# nrf9230_enga_celldsp register map
Vendor: Nordic Semiconductor; Series: nRF92; File version: 1
Registers are 32-bit, read-write, reset 0x0 unless marked. A register's access mark holds for its fields unless they carry their own. Offsets are from the block's base; [hi:lo] are bit positions; {n}, {i} and the like mark numbered series; 'fields as' and 'values as' point back to an identical list.

## HARQ — LTE HARQ
Base 0x4500C000
0x00 TASKS_STARTHARQCOMB wo — Start HARQ combining
  [0] TASKS_STARTHARQCOMB
    1=Trigger task
0x04 TASKS_STARTRM wo — Start rate de-mathcing and de-interleaving
  [0] TASKS_STARTRM
    1=Trigger task
0x08 TASKS_STARTUNPACK wo — Star HARQ process data unpacking operation
  [0] TASKS_STARTUNPACK
    1=Trigger task
0x0C TASKS_STARTPACK wo — Start HARQ process data packing operation
  [0] TASKS_STARTPACK
    1=Trigger task
0x10 TASKS_STARTBLKSCALE wo — Start data scaling factor calculation
  [0] TASKS_STARTBLKSCALE
    1=Trigger task
0x14 TASKS_STARTMEMSET wo — Start memory clearing
  [0] TASKS_STARTMEMSET
    1=Trigger task
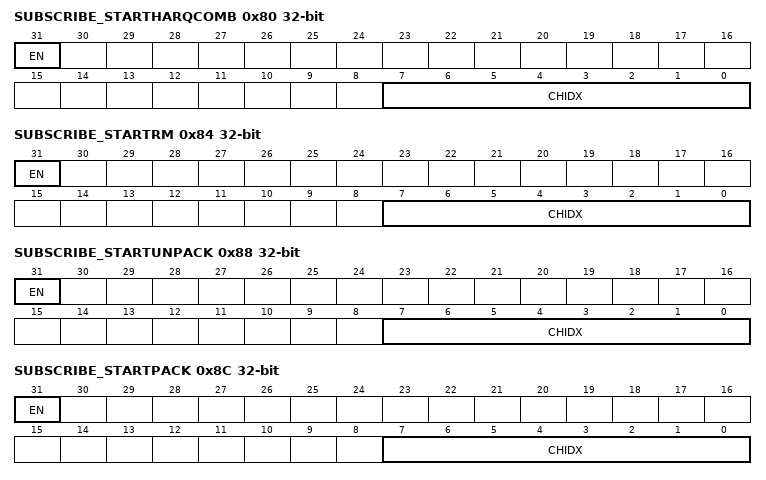
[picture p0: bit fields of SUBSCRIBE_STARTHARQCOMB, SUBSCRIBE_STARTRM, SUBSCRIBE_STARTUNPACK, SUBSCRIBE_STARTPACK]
0x80 SUBSCRIBE_STARTHARQCOMB — Subscribe configuration for task STARTHARQCOMB
  [31] EN
    0=Disabled (Disable subscription); 1=Enabled (Enable subscription)
  [7:0] CHIDX — DPPI channel that task STARTHARQCOMB will subscribe to
0x84 SUBSCRIBE_STARTRM — Subscribe configuration for task STARTRM
  [31] EN
    values as SUBSCRIBE_STARTHARQCOMB.EN
  [7:0] CHIDX — DPPI channel that task STARTRM will subscribe to
0x88 SUBSCRIBE_STARTUNPACK — Subscribe configuration for task STARTUNPACK
  [31] EN
    values as SUBSCRIBE_STARTHARQCOMB.EN
  [7:0] CHIDX — DPPI channel that task STARTUNPACK will subscribe to
0x8C SUBSCRIBE_STARTPACK — Subscribe configuration for task STARTPACK
  [31] EN
    values as SUBSCRIBE_STARTHARQCOMB.EN
  [7:0] CHIDX — DPPI channel that task STARTPACK will subscribe to
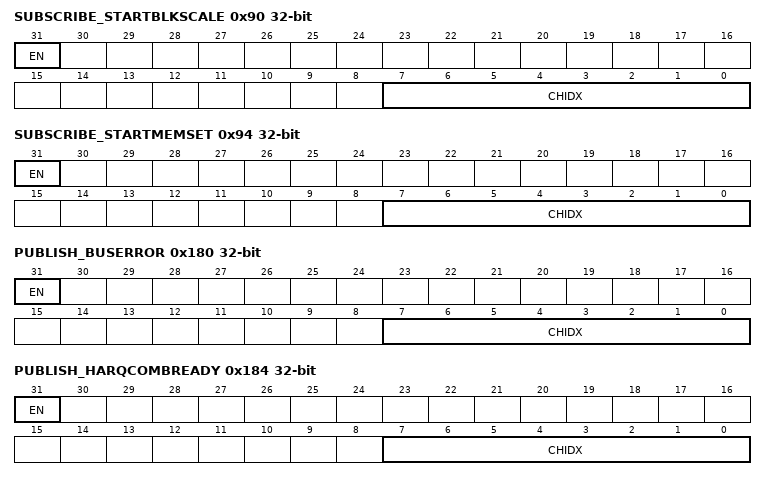
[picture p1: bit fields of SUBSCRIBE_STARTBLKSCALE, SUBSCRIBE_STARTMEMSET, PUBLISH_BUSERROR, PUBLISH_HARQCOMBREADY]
0x90 SUBSCRIBE_STARTBLKSCALE — Subscribe configuration for task STARTBLKSCALE
  [31] EN
    values as SUBSCRIBE_STARTHARQCOMB.EN
  [7:0] CHIDX — DPPI channel that task STARTBLKSCALE will subscribe to
0x94 SUBSCRIBE_STARTMEMSET — Subscribe configuration for task STARTMEMSET
  [31] EN
    values as SUBSCRIBE_STARTHARQCOMB.EN
  [7:0] CHIDX — DPPI channel that task STARTMEMSET will subscribe to
0x100 EVENTS_BUSERROR — AXI bus error response received
  [0] EVENTS_BUSERROR
    0=NotGenerated (Event not generated); 1=Generated (Event generated)
0x104 EVENTS_HARQCOMBREADY — HARQ combining ready
  [0] EVENTS_HARQCOMBREADY
    values as EVENTS_BUSERROR.EVENTS_BUSERROR
0x108 EVENTS_RMREADY — Rate de-matching and de-interleaving ready
  [0] EVENTS_RMREADY
    values as EVENTS_BUSERROR.EVENTS_BUSERROR
0x10C EVENTS_UNPACKREADY — HARQ data un-packed
  [0] EVENTS_UNPACKREADY
    values as EVENTS_BUSERROR.EVENTS_BUSERROR
0x110 EVENTS_PACKREADY — HARQ data packed
  [0] EVENTS_PACKREADY
    values as EVENTS_BUSERROR.EVENTS_BUSERROR
0x114 EVENTS_BLKSCALEREADY — Data scaling factor calculation ready
  [0] EVENTS_BLKSCALEREADY
    values as EVENTS_BUSERROR.EVENTS_BUSERROR
0x118 EVENTS_MEMSETREADY — Memory clearing ready
  [0] EVENTS_MEMSETREADY
    values as EVENTS_BUSERROR.EVENTS_BUSERROR
0x11C EVENTS_ERROR — Calculation error event
  [0] EVENTS_ERROR
    values as EVENTS_BUSERROR.EVENTS_BUSERROR
0x180 PUBLISH_BUSERROR — Publish configuration for event BUSERROR
  [31] EN
    0=Disabled (Disable publishing); 1=Enabled (Enable publishing)
  [7:0] CHIDX — DPPI channel that event BUSERROR will publish to
0x184 PUBLISH_HARQCOMBREADY — Publish configuration for event HARQCOMBREADY
  [31] EN
    values as PUBLISH_BUSERROR.EN
  [7:0] CHIDX — DPPI channel that event HARQCOMBREADY will publish to
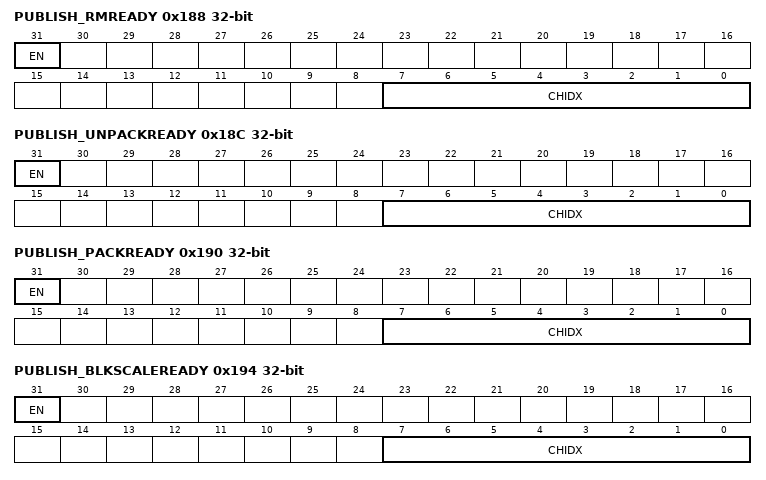
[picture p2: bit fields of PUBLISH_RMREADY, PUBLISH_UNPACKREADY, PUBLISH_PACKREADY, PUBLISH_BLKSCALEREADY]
0x188 PUBLISH_RMREADY — Publish configuration for event RMREADY
  [31] EN
    values as PUBLISH_BUSERROR.EN
  [7:0] CHIDX — DPPI channel that event RMREADY will publish to
0x18C PUBLISH_UNPACKREADY — Publish configuration for event UNPACKREADY
  [31] EN
    values as PUBLISH_BUSERROR.EN
  [7:0] CHIDX — DPPI channel that event UNPACKREADY will publish to
0x190 PUBLISH_PACKREADY — Publish configuration for event PACKREADY
  [31] EN
    values as PUBLISH_BUSERROR.EN
  [7:0] CHIDX — DPPI channel that event PACKREADY will publish to
0x194 PUBLISH_BLKSCALEREADY — Publish configuration for event BLKSCALEREADY
  [31] EN
    values as PUBLISH_BUSERROR.EN
  [7:0] CHIDX — DPPI channel that event BLKSCALEREADY will publish to
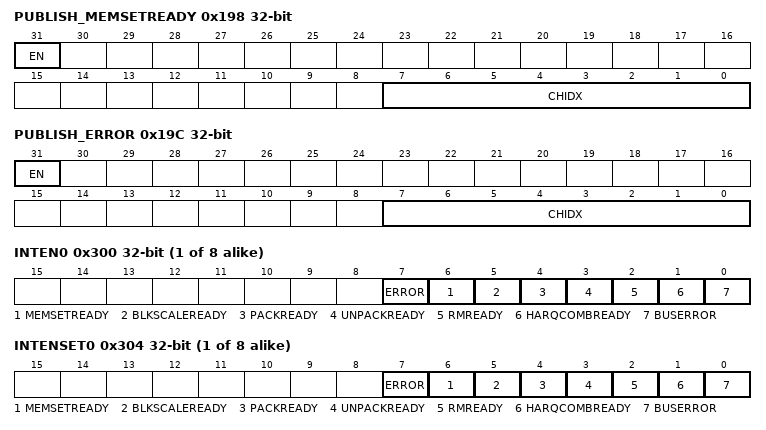
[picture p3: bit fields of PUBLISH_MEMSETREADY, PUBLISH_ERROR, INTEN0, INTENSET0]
0x198 PUBLISH_MEMSETREADY — Publish configuration for event MEMSETREADY
  [31] EN
    values as PUBLISH_BUSERROR.EN
  [7:0] CHIDX — DPPI channel that event MEMSETREADY will publish to
0x19C PUBLISH_ERROR — Publish configuration for event ERROR
  [31] EN
    values as PUBLISH_BUSERROR.EN
  [7:0] CHIDX — DPPI channel that event ERROR will publish to
{0x300+0x10*i} INTEN{i} (i=0..7) — Enable or disable interrupt
  [all] fields
    0=Disabled; 1=Enabled
  [7] ERROR — Enable or disable interrupt for event ERROR
  [6] MEMSETREADY — Enable or disable interrupt for event MEMSETREADY
  [5] BLKSCALEREADY — Enable or disable interrupt for event BLKSCALEREADY
  [4] PACKREADY — Enable or disable interrupt for event PACKREADY
  [3] UNPACKREADY — Enable or disable interrupt for event UNPACKREADY
  [2] RMREADY — Enable or disable interrupt for event RMREADY
  [1] HARQCOMBREADY — Enable or disable interrupt for event HARQCOMBREADY
  [0] BUSERROR — Enable or disable interrupt for event BUSERROR
{0x304+0x10*i} INTENSET{i} (i=0..7) — Enable interrupt
  [all] fields
    on read: 0=Disabled (Read: Disabled); 1=Enabled (Read: Enabled) | on write: 1=Set (Enable)
  [7] ERROR — Write '1' to enable interrupt for event ERROR
  [6] MEMSETREADY — Write '1' to enable interrupt for event MEMSETREADY
  [5] BLKSCALEREADY — Write '1' to enable interrupt for event BLKSCALEREADY
  [4] PACKREADY — Write '1' to enable interrupt for event PACKREADY
  [3] UNPACKREADY — Write '1' to enable interrupt for event UNPACKREADY
  [2] RMREADY — Write '1' to enable interrupt for event RMREADY
  [1] HARQCOMBREADY — Write '1' to enable interrupt for event HARQCOMBREADY
  [0] BUSERROR — Write '1' to enable interrupt for event BUSERROR
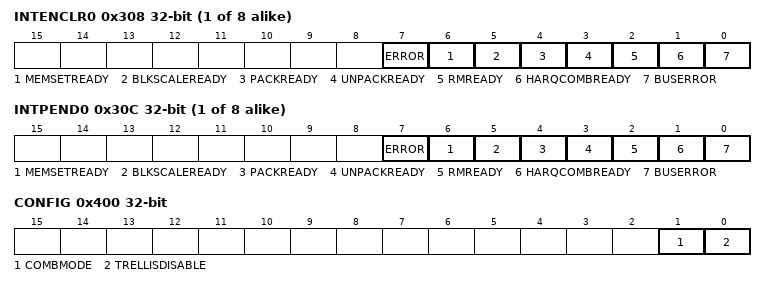
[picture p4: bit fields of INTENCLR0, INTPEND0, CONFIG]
{0x308+0x10*i} INTENCLR{i} (i=0..7) — Disable interrupt
  [all] fields
    on read: 0=Disabled (Read: Disabled); 1=Enabled (Read: Enabled) | on write: 1=Clear (Disable)
  [7] ERROR — Write '1' to disable interrupt for event ERROR
  [6] MEMSETREADY — Write '1' to disable interrupt for event MEMSETREADY
  [5] BLKSCALEREADY — Write '1' to disable interrupt for event BLKSCALEREADY
  [4] PACKREADY — Write '1' to disable interrupt for event PACKREADY
  [3] UNPACKREADY — Write '1' to disable interrupt for event UNPACKREADY
  [2] RMREADY — Write '1' to disable interrupt for event RMREADY
  [1] HARQCOMBREADY — Write '1' to disable interrupt for event HARQCOMBREADY
  [0] BUSERROR — Write '1' to disable interrupt for event BUSERROR
{0x30C+0x10*i} INTPEND{i} ro (i=0..7) — Pending interrupts
  [all] fields
    on read: 0=NotPending (Read: Not pending); 1=Pending (Read: Pending)
  [7] ERROR — Read pending status of interrupt for event ERROR
  [6] MEMSETREADY — Read pending status of interrupt for event MEMSETREADY
  [5] BLKSCALEREADY — Read pending status of interrupt for event BLKSCALEREADY
  [4] PACKREADY — Read pending status of interrupt for event PACKREADY
  [3] UNPACKREADY — Read pending status of interrupt for event UNPACKREADY
  [2] RMREADY — Read pending status of interrupt for event RMREADY
  [1] HARQCOMBREADY — Read pending status of interrupt for event HARQCOMBREADY
  [0] BUSERROR — Read pending status of interrupt for event BUSERROR
0x400 CONFIG — HARQ configuration register
  [1] COMBMODE — Combining mode select
    0=Normal combining; 1=Repetition final combining
  [0] TRELLISDISABLE — Turbo trellis re-ordering disable
    0=Enable (Trellis re-ordering is enabled); 1=Disable (Trellis re-ordering is disabled)
0x404 NCB — Code block size
  [15:0] NCB — Code block size. (Number of soft bits)
0x408 CBHARQBUFFSTARTADDR — HARQ buffer code block start address
0x40C SBUFFSTARTADDR — Soft buffer start address
  [31:0] SBUFFSTARTADDR — Soft buffer start address for HARQ or repetition combining
0x410 NBITSYMB — Bits per symbol
  [15:0] NBITSYMB — Bits per symbol for HARQ or repetition combining
0x414 SYMSTARTADDR — Symbol start address
  [31:0] SYMSTARTADDR — Symbol start address from input buffer
0x418 SYMOUTADDR — Symbol address to repetition buffer
  [31:0] SYMOUTADDR — Symbol start address to repetition buffer
0x41C MEMCLRSTARTADDR — Memory clearing start address
0x420 MEMCLRSIZE — Size of memory area to be cleared
  [31:0] MEMCLRSIZE — Size (bytes) of memory area to be cleared
0x424 SYSBITSOUTSTARTADDR — Systematic bits output buffer start address
0x428 P1OUTSTARTADDR — Parity one bits output buffer start address
0x42C P2OUTSTARTADDR — Parity two bits output buffer start address
0x430 P1NULLCOUNT — Array to hold number of dummy bits in each column in the s or p1 sub-block matrix
0x434 P2NULLCOUNT — Array to hold number of dummy bits in each column in the p2 sub-block matrix
0x438 DEMATCHERINBUFFSTARTADDR — Rate de-matcher input buffer start address
0x43C RSUBBLOCKTC — Interleaving matrix row count
  [7:0] RSUBBLOCKTC
0x440 SCALEVALUE — PDSCH block 16b to 8b scaling value
  [15:0] SCALEVALUE — PDSCH block 16b to 8b scaling value. Output of task BLKSCALE or overwritten by DSP
0x444 INVSCALEVALUE — PDSCH block 16b to 8b scaling value
  [15:0] INVSCALEVALUE — PDSCH block 16b to 8b scaling value. Output of task BLKSCALE or overwritten by DSP
0x448 HARQSCALEVALUE — Soft bit AGC set value
  [15:0] HARQSCALEVALUE
0x44C INVHARQSCALEVALUE — Soft bit AGC inverse set value
  [15:0] INVHARQSCALEVALUE
0x450 KW — kW (without nulls)
  [15:0] KW
0x454 TURBOSCAL
  [7:0] TURBOSCAL — Turbo scaling factor
0x458 SWAPTRELLISSYSIDX5AND7
  [0] SWAPTRELLISSYSIDX5AND7 — Swap Turbo trellis swapping s bits index 5 and 7
0x45C KVAL — k value
  [15:0] KVAL
0x460 POSTSHIFT1RNDCONSTPLUS reset 0x1
  [31:0] POSTSHIFT1RNDCONSTPLUS — Shift rounding constant. 1b shift, for pos values
0x464 POSTSHIFT1RNDCONSTMINUS
  [31:0] POSTSHIFT1RNDCONSTMINUS — Shift rounding constant. 1b shift, for neg values
0x468 POSTSHIFT8RNDCONSTPLUS reset 0xFF
  [31:0] POSTSHIFT8RNDCONSTPLUS — Shift rounding constant. 8b shift, for pos values
0x46C POSTSHIFT8RNDCONSTMINUS
  [31:0] POSTSHIFT8RNDCONSTMINUS — Shift rounding constant. 8b shift, for neg values
0x470 POSTSHIFT16RNDCONSTPLUS reset 0xFFFF
  [31:0] POSTSHIFT16RNDCONSTPLUS — Shift rounding constant. 16b shift, for pos values
0x474 POSTSHIFT16RNDCONSTMINUS
  [31:0] POSTSHIFT16RNDCONSTMINUS — Shift rounding constant. 16b shift, for neg values
0x478 NORMVALUE
  [15:0] NORMVALUE — Mean of combined softbit absolute values
0x47C NUMNONZEROSBITS
  [15:0] NUMNONZEROSBITS — Number of non-zero softbit absolute values

## Notices in the file
Copyright (c) 2010 - 2024, Nordic Semiconductor ASA
All rights reserved.
Redistribution and use in source and binary forms, with or without modification,
are permitted provided that the following conditions are met:
1. Redistributions of source code must retain the above copyright notice, this
list of conditions and the following disclaimer.
2. Redistributions in binary form, except as embedded into a Nordic
Semiconductor ASA integrated circuit in a product or a software update for
such product, must reproduce the above copyright notice, this list of
conditions and the following disclaimer in the documentation and/or other
materials provided with the distribution.
3. Neither the name of Nordic Semiconductor ASA nor the names of its
contributors may be used to endorse or promote products derived from this
software without specific prior written permission.
4. This software, with or without modification, must only be used with a
Nordic Semiconductor ASA integrated circuit.
5. Any software provided in binary form under this license must not be reverse
engineered, decompiled, modified and/or disassembled.
THIS SOFTWARE IS PROVIDED BY NORDIC SEMICONDUCTOR ASA "AS IS" AND ANY EXPRESS
OR IMPLIED WARRANTIES, INCLUDING, BUT NOT LIMITED TO, THE IMPLIED WARRANTIES
OF MERCHANTABILITY, NONINFRINGEMENT, AND FITNESS FOR A PARTICULAR PURPOSE ARE
DISCLAIMED. IN NO EVENT SHALL NORDIC SEMICONDUCTOR ASA OR CONTRIBUTORS BE
LIABLE FOR ANY DIRECT, INDIRECT, INCIDENTAL, SPECIAL, EXEMPLARY, OR
CONSEQUENTIAL DAMAGES (INCLUDING, BUT NOT LIMITED TO, PROCUREMENT OF SUBSTITUTE
GOODS OR SERVICES; LOSS OF USE, DATA, OR PROFITS; OR BUSINESS INTERRUPTION)
HOWEVER CAUSED AND ON ANY THEORY OF LIABILITY, WHETHER IN CONTRACT, STRICT
LIABILITY, OR TORT (INCLUDING NEGLIGENCE OR OTHERWISE) ARISING IN ANY WAY OUT
OF THE USE OF THIS SOFTWARE, EVEN IF ADVISED OF THE POSSIBILITY OF SUCH DAMAGE.
